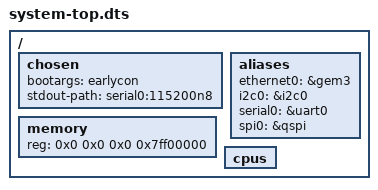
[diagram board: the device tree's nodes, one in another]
/*
 * CAUTION: This file is automatically generated by Xilinx.
 * Version: XSCT 2022.1
 * Today is: Mon Jun 20 14:47:50 2022
 */


/dts-v1/;
#include "zynqmp.dtsi"
#include "zynqmp-clk-ccf.dtsi"
#include "pl.dtsi"
#include "pcw.dtsi"
/ {
	chosen {
		bootargs = "earlycon";
		stdout-path = "serial0:115200n8";
	};
	aliases {
		ethernet0 = &gem3;
		i2c0 = &i2c0;
		serial0 = &uart0;
		spi0 = &qspi;
	};
	memory {
		device_type = "memory";
		reg = <0x0 0x0 0x0 0x7ff00000>;
	};
	cpus {
		/delete-node/ cpu@2 ;
		/delete-node/ cpu@3 ;
	};
};
